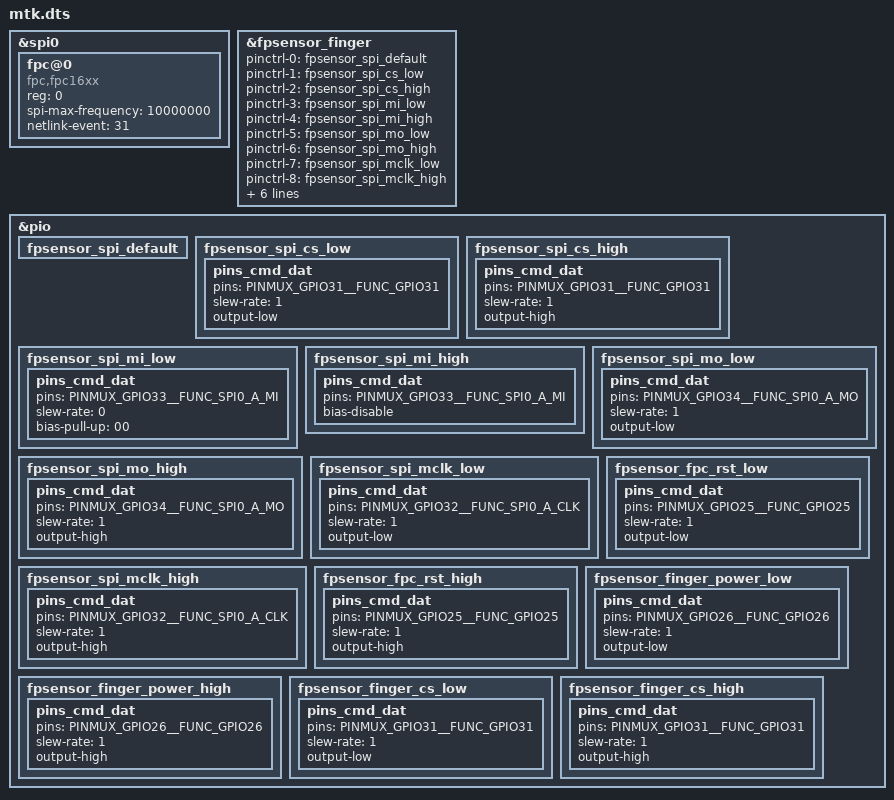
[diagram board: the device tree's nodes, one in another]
#include <generated/autoconf.h>
/dts-v1/;

&spi0 {
	#address-cells = <1>;
	#size-cells = <0>;
	fpc@0 {
		compatible = "fpc,fpc16xx";
		reg = <0>;
		spi-max-frequency = <10000000>;
		netlink-event = <31>;
		status = "okay";
	};
};

&fpsensor_finger {
	pinctrl-names = "fpsensor_spi_default", "fpsensor_spi_cs_low", "fpsensor_spi_cs_high",
			"fpsensor_spi_mi_low", "fpsensor_spi_mi_high", "fpsensor_spi_mo_low",
			"fpsensor_spi_mo_high", "fpsensor_spi_mclk_low", "fpsensor_spi_mclk_high",
			"fpsensor_fpc_rst_low", "fpsensor_fpc_rst_high",
			"fpsensor_finger_power_low","fpsensor_finger_power_high",
			"fpsensor_finger_cs_low", "fpsensor_finger_cs_high";
	pinctrl-0 = <&fpsensor_spi_default>;
	pinctrl-1 = <&fpsensor_spi_cs_low>;
	pinctrl-2 = <&fpsensor_spi_cs_high>;
	pinctrl-3 = <&fpsensor_spi_mi_low>;
	pinctrl-4 = <&fpsensor_spi_mi_high>;
	pinctrl-5 = <&fpsensor_spi_mo_low>;
	pinctrl-6 = <&fpsensor_spi_mo_high>;
	pinctrl-7 = <&fpsensor_spi_mclk_low>;
	pinctrl-8 = <&fpsensor_spi_mclk_high>;
	pinctrl-9 = <&fpsensor_fpc_rst_low>;
	pinctrl-10 = <&fpsensor_fpc_rst_high>;
	pinctrl-11 = <&fpsensor_finger_power_low>;
	pinctrl-12 = <&fpsensor_finger_power_high>;
	pinctrl-16 = <&fpsensor_finger_cs_low>;
	pinctrl-17 = <&fpsensor_finger_cs_high>;
	status = "okay";
};

&pio {
	fpsensor_spi_default: fpsensor_spi_default {
	};

	fpsensor_spi_cs_low: fpsensor_spi_cs_low {
		pins_cmd_dat {
			pins = <PINMUX_GPIO31__FUNC_GPIO31>;
			slew-rate = <1>;
			output-low;
		};
	};
	fpsensor_spi_cs_high: fpsensor_spi_cs_high {
		pins_cmd_dat {
			pins = <PINMUX_GPIO31__FUNC_GPIO31>;
			slew-rate = <1>;
			output-high;
		};
	};

	fpsensor_spi_mi_low: fpsensor_spi_mi_low {
		pins_cmd_dat {
			pins = <PINMUX_GPIO33__FUNC_SPI0_A_MI>;
			slew-rate = <0>;
			bias-pull-up = <00>;
		};
	};

	fpsensor_spi_mi_high: fpsensor_spi_mi_high {
		pins_cmd_dat {
			pins = <PINMUX_GPIO33__FUNC_SPI0_A_MI>;
			bias-disable;
		};
	};

	fpsensor_spi_mo_low: fpsensor_spi_mo_low {
		pins_cmd_dat {
			pins = <PINMUX_GPIO34__FUNC_SPI0_A_MO>;
			slew-rate = <1>;
			output-low;
		};
	};

	fpsensor_spi_mo_high: fpsensor_spi_mo_high {
		pins_cmd_dat {
			pins = <PINMUX_GPIO34__FUNC_SPI0_A_MO>;
			slew-rate = <1>;
			output-high;
		};
	};

	fpsensor_spi_mclk_low: fpsensor_spi_mclk_low {
		pins_cmd_dat {
			pins = <PINMUX_GPIO32__FUNC_SPI0_A_CLK>;
			slew-rate = <1>;
			output-low;
		};
	};

	fpsensor_spi_mclk_high: fpsensor_spi_mclk_high {
		pins_cmd_dat {
			pins = <PINMUX_GPIO32__FUNC_SPI0_A_CLK>;
			slew-rate = <1>;
			output-high;
		};
	};

	fpsensor_fpc_rst_low: fpsensor_fpc_rst_low {
		pins_cmd_dat {
			pins = <PINMUX_GPIO25__FUNC_GPIO25>;
			slew-rate = <1>;
			output-low;
		};
	};

	fpsensor_fpc_rst_high: fpsensor_fpc_rst_high {
		pins_cmd_dat {
			pins = <PINMUX_GPIO25__FUNC_GPIO25>;
			slew-rate = <1>;
			output-high;
		};
	};

	fpsensor_finger_power_low: fpsensor_finger_power_low {
		pins_cmd_dat {
			pins = <PINMUX_GPIO26__FUNC_GPIO26>;
			slew-rate = <1>;
			output-low;
		};
	};

	fpsensor_finger_power_high: fpsensor_finger_power_high {
		pins_cmd_dat {
			pins = <PINMUX_GPIO26__FUNC_GPIO26>;
			slew-rate = <1>;
			output-high;
		};
	};

	fpsensor_finger_cs_low: fpsensor_finger_cs_low {
		pins_cmd_dat {
			pins = <PINMUX_GPIO31__FUNC_GPIO31>;
			slew-rate = <1>;
			output-low;
		};
	};

	fpsensor_finger_cs_high: fpsensor_finger_cs_high {
		pins_cmd_dat {
			pins = <PINMUX_GPIO31__FUNC_GPIO31>;
			slew-rate = <1>;
			output-high;
		};
	};
};
